# STM32C591xx register map
File version: 1.0
Registers are 32-bit, read-write, reset 0x0 unless marked. A register's access mark holds for its fields unless they carry their own. Offsets are from the block's base; [hi:lo] are bit positions.

## USART2 — Universal Synchronous Asynchronous Receiver Transmitter
Base 0x40004400
Same registers: USART3 0x40004800, UART4 0x40004C00, UART5 0x40005000, USART6 0x40006400, UART7 0x40007800, USART1 0x40013800, LPUART1 0x44002400
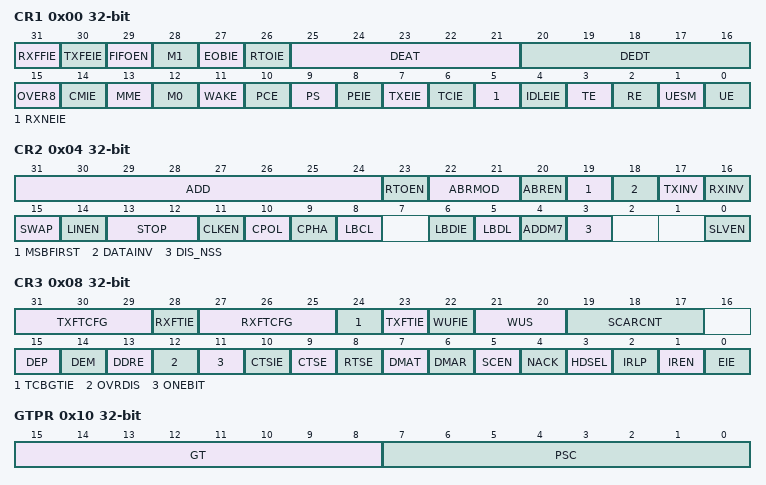
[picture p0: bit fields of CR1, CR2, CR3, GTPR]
0x00 CR1 — USART Control register 1
  [31] RXFFIE — RX FIFO Full Interrupt Enable
  [30] TXFEIE — TX FIFO Empty Interrupt Enable
  [29] FIFOEN — FIFO mode enable
  [28] M1 — Word length - Bit 1
  [27] EOBIE — End of Block Interrupt Enable
  [26] RTOIE — Receive Time Out Interrupt Enable
  [25:21] DEAT — DEAT[4:0] bits (Driver Enable Assertion Time)
  [20:16] DEDT — DEDT[4:0] bits (Driver Enable Deassertion Time)
  [15] OVER8 — Oversampling by 8-bit or 16-bit mode
  [14] CMIE — Character match Interrupt Enable
  [13] MME — Mute Mode Enable
  [12] M0 — Word length - Bit 0
  [11] WAKE — Receiver Wakeup method
  [10] PCE — Parity Control Enable
  [9] PS — Parity Selection
  [8] PEIE — PE Interrupt Enable
  [7] TXEIE — TXE Interrupt Enable
  [6] TCIE — Transmission Complete Interrupt Enable
  [5] RXNEIE — RXNE Interrupt Enable
  [4] IDLEIE — IDLE Interrupt Enable
  [3] TE — Transmitter Enable
  [2] RE — Receiver Enable
  [1] UESM — USART Enable in STOP Mode
  [0] UE — USART Enable
0x04 CR2 — USART Control register 2
  [31:24] ADD — Address of the USART node
  [23] RTOEN — Receiver Time-Out enable
  [22:21] ABRMOD — ABRMOD[1:0] bits (Auto Baud-Rate Mode)
  [20] ABREN — Auto Baud-Rate Enable
  [19] MSBFIRST — Most Significant Bit First
  [18] DATAINV — Binary data inversion
  [17] TXINV — TX pin active level inversion
  [16] RXINV — RX pin active level inversion
  [15] SWAP — SWAP TX/RX pins
  [14] LINEN — LIN mode enable
  [13:12] STOP — STOP[1:0] bits (STOP bits)
  [11] CLKEN — Clock Enable
  [10] CPOL — Clock Polarity
  [9] CPHA — Clock Phase
  [8] LBCL — Last Bit Clock pulse
  [6] LBDIE — LIN Break Detection Interrupt Enable
  [5] LBDL — LIN Break Detection Length
  [4] ADDM7 — 7-bit or 4-bit Address Detection
  [3] DIS_NSS — Slave Select (NSS) pin management
  [0] SLVEN — Synchronous Slave mode enable
0x08 CR3 — USART Control register 3
  [31:29] TXFTCFG — TX FIFO Threshold configuration
  [28] RXFTIE — RX FIFO Threshold Interrupt Enable
  [27:25] RXFTCFG — RX FIFO Threshold Configuration
  [24] TCBGTIE — Transmission Complete Before Guard Time Interrupt Enable
  [23] TXFTIE — TX FIFO Threshold Interrupt Enable
  [22] WUFIE — Wake Up Interrupt Enable
  [21:20] WUS — WUS[1:0] bits (Wake UP Interrupt Flag Selection)
  [19:17] SCARCNT — SCARCNT[2:0] bits (SmartCard Auto-Retry Count)
  [15] DEP — Driver Enable Polarity Selection
  [14] DEM — Driver Enable Mode
  [13] DDRE — DMA Disable on Reception Error
  [12] OVRDIS — Overrun Disable
  [11] ONEBIT — One sample bit method enable
  [10] CTSIE — CTS Interrupt Enable
  [9] CTSE — CTS Enable
  [8] RTSE — RTS Enable
  [7] DMAT — DMA Enable Transmitter
  [6] DMAR — DMA Enable Receiver
  [5] SCEN — SmartCard mode enable
  [4] NACK — SmartCard NACK enable
  [3] HDSEL — Half-Duplex Selection
  [2] IRLP — IrDA Low-Power
  [1] IREN — IrDA mode Enable
  [0] EIE — Error Interrupt Enable
0x0C BRR — USART Baud rate register
  [19:0] LPUART — LPUART Baud rate register [19:0]
0x10 GTPR — USART Guard time and prescaler register
  [15:8] GT — GT[7:0] bits (Guard time value)
  [7:0] PSC — PSC[7:0] bits (Prescaler value)
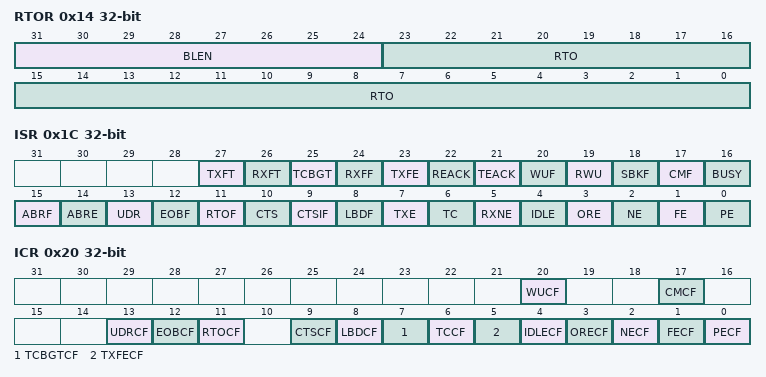
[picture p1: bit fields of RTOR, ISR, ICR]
0x14 RTOR — USART Receiver Time Out register
  [31:24] BLEN — Block Length
  [23:0] RTO — Receiver Time Out Value
0x18 RQR — USART Request register
0x1C ISR ro — USART Interrupt and status register
  [27] TXFT — TX FIFO Threshold Flag
  [26] RXFT — RX FIFO Threshold Flag
  [25] TCBGT — Transmission Complete Before Guard Time completion
  [24] RXFF — RX FIFO Full Flag
  [23] TXFE — TX FIFO Empty Flag
  [22] REACK — Receive Enable Acknowledge Flag
  [21] TEACK — Transmit Enable Acknowledge Flag
  [20] WUF — Wake Up from low power mode Flag
  [19] RWU — Receive Wake Up from mute mode Flag
  [18] SBKF — Send Break Flag
  [17] CMF — Character Match Flag
  [16] BUSY — Busy Flag
  [15] ABRF — Auto-Baud Rate Flag
  [14] ABRE — Auto-Baud Rate Error
  [13] UDR — SPI Slave Underrun error Flag
  [12] EOBF — End Of Block Flag
  [11] RTOF — Receiver Time Out
  [10] CTS — CTS Flag
  [9] CTSIF — CTS interrupt Flag
  [8] LBDF — LIN Break Detection Flag
  [7] TXE — Transmit Data Register Empty
  [6] TC — Transmission Complete
  [5] RXNE — Read Data Register Not Empty
  [4] IDLE — IDLE line detected
  [3] ORE — OverRun Error
  [2] NE — Noise Error detection Flag
  [1] FE — Framing Error
  [0] PE — Parity Error
0x20 ICR — USART Interrupt flag Clear register
  [20] WUCF — Wake Up from stop mode Clear Flag
  [17] CMCF — Character Match Clear Flag
  [13] UDRCF — SPI Slave Underrun Clear Flag
  [12] EOBCF — End Of Block Clear Flag
  [11] RTOCF — Receiver Time Out Clear Flag
  [9] CTSCF — CTS Interrupt Clear Flag
  [8] LBDCF — LIN Break Detection Clear Flag
  [7] TCBGTCF — Transmission Complete Before Guard Time Clear Flag
  [6] TCCF — Transmission Complete Clear Flag
  [5] TXFECF — TX FIFO Empty Clear Flag
  [4] IDLECF — IDLE line detected Clear Flag
  [3] ORECF — OverRun Error Clear Flag
  [2] NECF — Noise Error detected Clear Flag
  [1] FECF — Framing Error Clear Flag
  [0] PECF — Parity Error Clear Flag
0x24 RDR ro — USART Receive Data register
0x28 TDR — USART Transmit Data register
0x2C PRESC — USART Prescaler register
  [3:0] PRESCALER — PRESCALER[3:0] bits (Clock prescaler)
